# COMPUTE_CLUSTER0_DRU_MMR_FW register map
Vendor: Texas Instruments
Peripheral module from a debugger description file (folder J7ES).
Registers are 32-bit, read-write, reset 0x0 unless marked. A register's access mark holds for its fields unless they carry their own. Offsets are as the file gives them; lines under a group give offsets from that group; [hi:lo] are bit positions; {n}, {i} and the like mark numbered series; 'fields as' and 'values as' point back to an identical list; <NAME> marks a mode.

## COMPUTE_CLUSTER0_DRU_MMR_FW
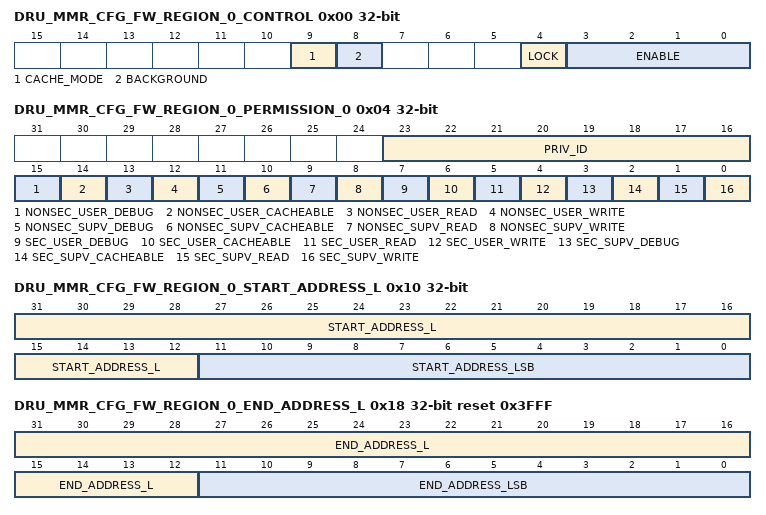
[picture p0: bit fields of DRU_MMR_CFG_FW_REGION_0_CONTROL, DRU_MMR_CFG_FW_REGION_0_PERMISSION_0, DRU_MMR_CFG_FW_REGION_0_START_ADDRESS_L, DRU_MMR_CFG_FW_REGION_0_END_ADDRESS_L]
0x00 DRU_MMR_CFG_FW_REGION_0_CONTROL access not given — The FW Region 0 Control Register defines the control fields for the slave mmr.dru_mmr_cfg region 0 firewall.
  [9] CACHE_MODE rw — Cache mode for region.
  [8] BACKGROUND rw — Background enable for region.
  [4] LOCK — Lock region. (access RW1S)
  [3:0] ENABLE rw — Enable region.
0x04 DRU_MMR_CFG_FW_REGION_0_PERMISSION_0 — The FW Region 0 Permission 0 Register defines the permissions for the slave mmr.dru_mmr_cfg region 0 firewall.
  [23:16] PRIV_ID — Allowed privid.
  [15] NONSEC_USER_DEBUG — Non-secure user debug allowed.
  [14] NONSEC_USER_CACHEABLE — Non-secure user cacheable allowed.
  [13] NONSEC_USER_READ — Non-secure user read allowed.
  [12] NONSEC_USER_WRITE — Non-secure user write allowed.
  [11] NONSEC_SUPV_DEBUG — Non-secure supervisor debug allowed.
  [10] NONSEC_SUPV_CACHEABLE — Non-secure supervisor cacheable allowed.
  [9] NONSEC_SUPV_READ — Non-secure supervisor read allowed.
  [8] NONSEC_SUPV_WRITE — Non-secure supervisor write allowed.
  [7] SEC_USER_DEBUG — Secure user debug allowed.
  [6] SEC_USER_CACHEABLE — Secure user cacheable allowed.
  [5] SEC_USER_READ — Secure user read allowed.
  [4] SEC_USER_WRITE — Secure user write allowed.
  [3] SEC_SUPV_DEBUG — Secure supervisor debug allowed.
  [2] SEC_SUPV_CACHEABLE — Secure supervisor cacheable allowed.
  [1] SEC_SUPV_READ — Secure supervisor read allowed.
  [0] SEC_SUPV_WRITE — Secure supervisor write allowed.
0x10 DRU_MMR_CFG_FW_REGION_0_START_ADDRESS_L access per field — The FW Region 0 Start Address Low Register defines the start address bits 31 to 0 for the slave mmr.dru_mmr_cfg region 0 firewall.
  [31:12] START_ADDRESS_L rw — Start address bits 31 to 12.
  [11:0] START_ADDRESS_LSB ro — Start address bits 11 to 0 are forced to 0 as address must be 4KB aligned.
0x14 DRU_MMR_CFG_FW_REGION_0_START_ADDRESS_H — The FW Region 0 Start Address High Register defines the start address bits 47 to 32 for the slave mmr.dru_mmr_cfg region 0 firewall.
  [15:0] START_ADDRESS_H — Start address bits 47 to 32.
0x18 DRU_MMR_CFG_FW_REGION_0_END_ADDRESS_L access per field reset 0x3FFF — The FW Region 0 End Address Low Register defines the end address bits 31 to 0 to include for the slave mmr.dru_mmr_cfg region 0 firewall.
  [31:12] END_ADDRESS_L rw — End address bits 31 to 12 to include in the match.
  [11:0] END_ADDRESS_LSB ro — End address bits 11 to 0 are forced to 1s as address must be 4KB aligned minus 1.
0x1C DRU_MMR_CFG_FW_REGION_0_END_ADDRESS_H — The FW Region 0 End Address High Register defines the end address bits 47 to 32 to include for the slave mmr.dru_mmr_cfg region 0 firewall.
  [15:0] END_ADDRESS_H — End address bits 47 to 32 to include in the match.
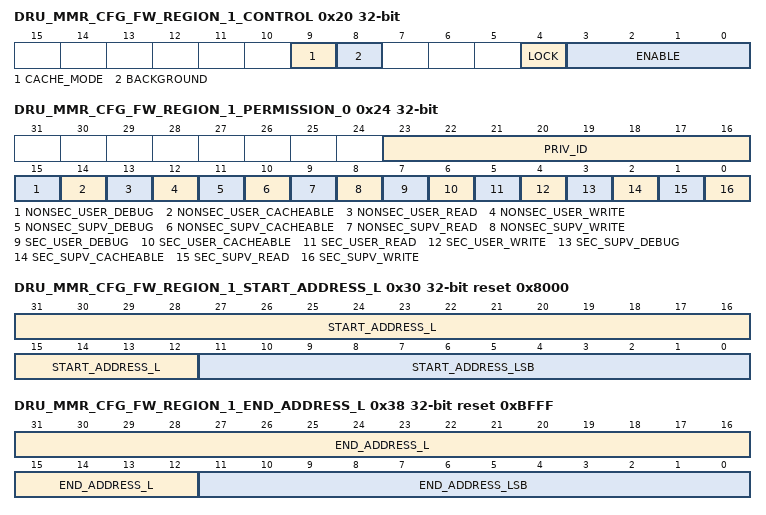
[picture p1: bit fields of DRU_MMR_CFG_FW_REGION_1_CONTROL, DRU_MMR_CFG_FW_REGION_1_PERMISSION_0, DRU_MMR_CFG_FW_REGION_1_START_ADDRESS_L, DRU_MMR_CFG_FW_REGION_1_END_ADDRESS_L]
0x20 DRU_MMR_CFG_FW_REGION_1_CONTROL access not given — The FW Region 1 Control Register defines the control fields for the slave mmr.dru_mmr_cfg region 1 firewall.
  fields as DRU_MMR_CFG_FW_REGION_0_CONTROL
0x24 DRU_MMR_CFG_FW_REGION_1_PERMISSION_0 — The FW Region 1 Permission 0 Register defines the permissions for the slave mmr.dru_mmr_cfg region 1 firewall.
  fields as DRU_MMR_CFG_FW_REGION_0_PERMISSION_0
0x30 DRU_MMR_CFG_FW_REGION_1_START_ADDRESS_L access per field reset 0x8000 — The FW Region 1 Start Address Low Register defines the start address bits 31 to 0 for the slave mmr.dru_mmr_cfg region 1 firewall.
  fields as DRU_MMR_CFG_FW_REGION_0_START_ADDRESS_L
0x34 DRU_MMR_CFG_FW_REGION_1_START_ADDRESS_H — The FW Region 1 Start Address High Register defines the start address bits 47 to 32 for the slave mmr.dru_mmr_cfg region 1 firewall.
  [15:0] START_ADDRESS_H — Start address bits 47 to 32.
0x38 DRU_MMR_CFG_FW_REGION_1_END_ADDRESS_L access per field reset 0xBFFF — The FW Region 1 End Address Low Register defines the end address bits 31 to 0 to include for the slave mmr.dru_mmr_cfg region 1 firewall.
  fields as DRU_MMR_CFG_FW_REGION_0_END_ADDRESS_L
0x3C DRU_MMR_CFG_FW_REGION_1_END_ADDRESS_H — The FW Region 1 End Address High Register defines the end address bits 47 to 32 to include for the slave mmr.dru_mmr_cfg region 1 firewall.
  fields as DRU_MMR_CFG_FW_REGION_0_END_ADDRESS_H
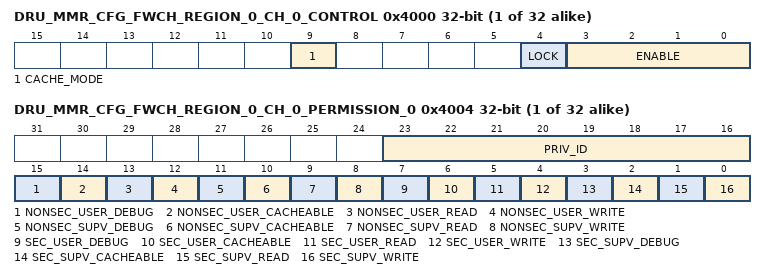
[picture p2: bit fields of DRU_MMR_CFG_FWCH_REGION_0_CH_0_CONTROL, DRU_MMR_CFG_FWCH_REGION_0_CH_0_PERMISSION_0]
{0x4000+0x20*i} DRU_MMR_CFG_FWCH_REGION_0_CH_{i}_CONTROL access not given (i=0..31) — The FW Region 0 Channel {i} Control Register defines the control fields for the slave mmr.dru_mmr_cfg region 0 channel {i} firewall.
  [9] CACHE_MODE rw — Cache mode for region.
  [4] LOCK — Lock region. (access RW1S)
  [3:0] ENABLE rw — Enable region.
{0x4004+0x20*i} DRU_MMR_CFG_FWCH_REGION_0_CH_{i}_PERMISSION_0 (i=0..31) — The FW Region 0 Channel {i} Permission 0 Register defines the permissions for the slave mmr.dru_mmr_cfg region 0 channel {i} firewall.
  fields as DRU_MMR_CFG_FW_REGION_0_PERMISSION_0
